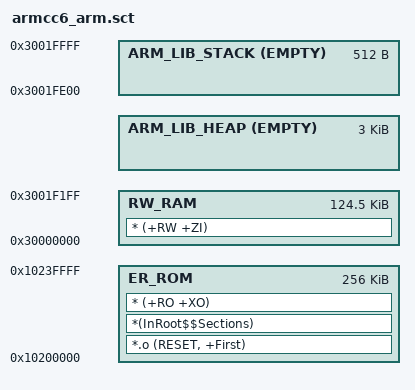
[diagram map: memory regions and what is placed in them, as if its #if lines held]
#! armclang -E --target=arm-arm-none-eabi -mcpu=cortex-m33 -xc
; command above MUST be in first line (no comment above!)

#if defined QSPI
  #define S_CODE_START   0x10200000
  #define S_CODE_SIZE    0x00040000
#elif defined MRAM
  #define S_CODE_START   0x1A000000
  #define S_CODE_SIZE    0x00200000
#else
  #define S_CODE_START   0x10000000
  #define S_CODE_SIZE    0x00200000
#endif
  #define S_DATA_START   0x30000000
  #define S_DATA_SIZE    0x00020000

/*
;-------- <<< Use Configuration Wizard in Context Menu >>> ------------------
*/

/*--------------------- Flash Configuration -------------------------
; <h> Flash Configuration
;   <o0> Flash Base Address <0x0-0xFFFFFFFF:8>
;   <o1> Flash Size (in Bytes) <0x0-0xFFFFFFFF:8>
; </h>
 *----------------------------------------------------------------------------*/
#define __ROM_BASE     S_CODE_START
#define __ROM_SIZE     S_CODE_SIZE

/*--------------------- Embedded RAM Configuration ---------------------------
; <h> RAM Configuration
;   <o0> RAM Base Address    <0x0-0xFFFFFFFF:8>
;   <o1> RAM Size (in Bytes) <0x0-0xFFFFFFFF:8>
; </h>
 *----------------------------------------------------------------------------*/
#define __RAM_BASE     S_DATA_START
#define __RAM_SIZE     S_DATA_SIZE

/*--------------------- Stack / Heap Configuration ---------------------------
; <h> Stack / Heap Configuration
;   <o0> Stack Size (in Bytes) <0x0-0xFFFFFFFF:8>
;   <o1> Heap Size (in Bytes) <0x0-0xFFFFFFFF:8>
; </h>
 *----------------------------------------------------------------------------*/
#define __STACK_SIZE       0x00000200
#define __HEAP_SIZE        0x00000C00


/*----------------------------------------------------------------------------
  User Stack & Heap boundery definition
 *----------------------------------------------------------------------------*/
#define __STACK_TOP        (__RAM_BASE + __RAM_SIZE)      /* starts at end of RAM */
#define __HEAP_BASE        (AlignExpr(+0, 8))             /* starts after RW_RAM section, 8 byte aligned */
//#define __HEAP_BASE        (__RAM_BASE + __RAM_SIZE - __STACK_SIZE - __HEAP_SIZE)


/*----------------------------------------------------------------------------
  Scatter File Definitions definition
 *----------------------------------------------------------------------------*/
#define __RO_BASE         __ROM_BASE
#define __RO_SIZE         __ROM_SIZE

#define __RW_BASE        (__RAM_BASE        )
#define __RW_SIZE        (__RAM_SIZE - __STACK_SIZE - __HEAP_SIZE)



LR_ROM __RO_BASE __RO_SIZE  {                       ; load region size_region
  ER_ROM __RO_BASE __RO_SIZE  {                     ; load address = execution address
    *.o (RESET, +First)
    *(InRoot$$Sections)
//    *(Veneer$$CMSE)                               ; uncomment to locate SG veneers
    * (+RO +XO)
  }
  
  RW_RAM __RW_BASE __RW_SIZE  {                     ; RW data
    * (+RW +ZI)
  }

  ARM_LIB_HEAP  __HEAP_BASE EMPTY  __HEAP_SIZE  { ; Reserve empty region for heap
  }

  ARM_LIB_STACK __STACK_TOP EMPTY -__STACK_SIZE { ; Reserve empty region for stack 
  }
}
